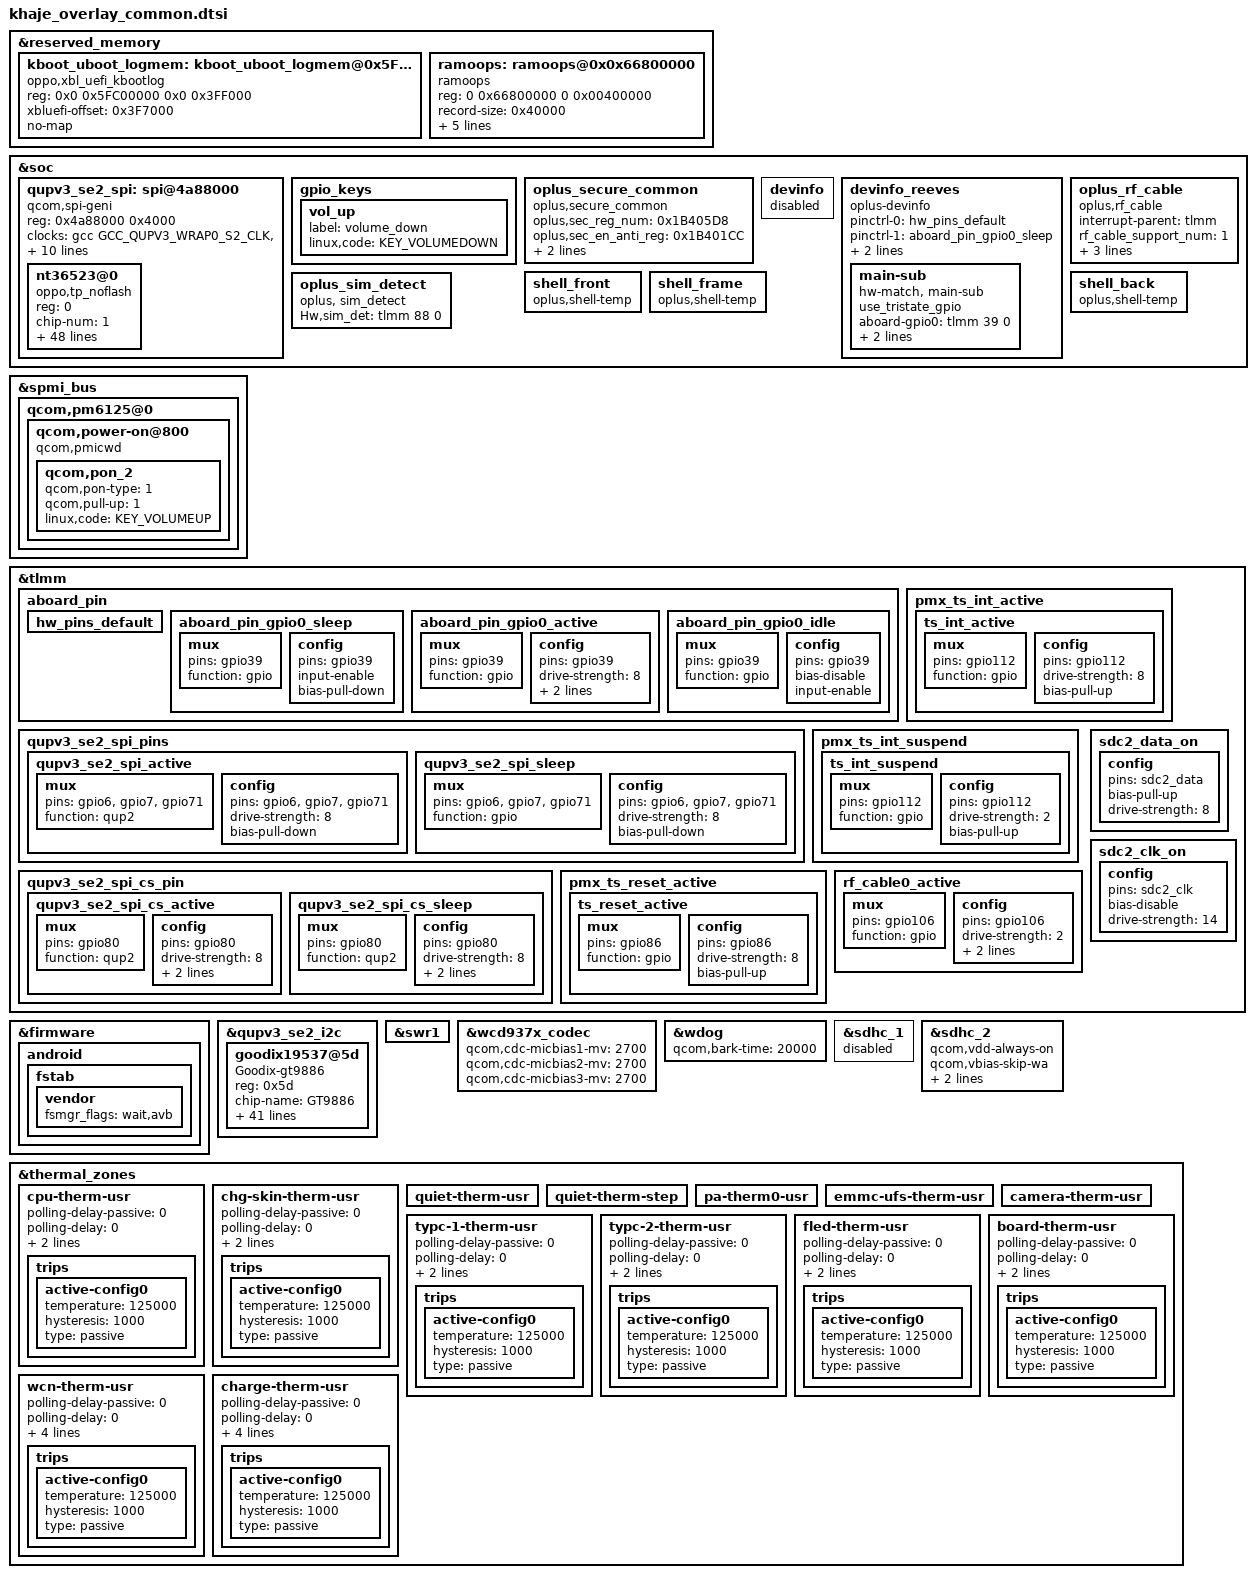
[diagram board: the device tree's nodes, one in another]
#include "dsi-panel-nt36523b-60hz-djn-reeves-fhd-video.dtsi"
#include "dsi-panel-nt36523w-60hz-inx-reeves-fhd-video.dtsi"
#include "camera/khaje-reeves-camera-overlay.dtsi"
#include "sensor/reeves-sensor-mtp.dtsi"

// xbl_uefi_mem address get from boot_images Core.dsc.inc file: PcdEmbeddedFdBaseAddress + SERIAL_BUFFER_OFFSET,0x5FC00000+0x3F7000
// kernel boot log: 0x5FC00000~ 0x5FFF7000
&reserved_memory {
	kboot_uboot_logmem: kboot_uboot_logmem@0x5FC00000 {
		reg = <0x0 0x5FC00000 0x0 0x3FF000>;
		compatible = "oppo,xbl_uefi_kbootlog";
		xbluefi-offset = <0x3F7000>;
		no-map;
	};

	ramoops: ramoops@0x0x66800000 {
		compatible = "ramoops";
		reg = <0 0x66800000 0 0x00400000>;
		record-size =  <0x40000>; //256x1024
		console-size = <0x40000>;
		ftrace-size =  <0x40000>;
		pmsg-size=         <0x200000>;
		devinfo-size=  <0x01000>;
		ecc-size=          <0x0>;
	};
};
//bengal-qrd.dtsi
&soc {
	qupv3_se2_spi: spi@4a88000 {
		compatible = "qcom,spi-geni";
		#address-cells = <1>;
		#size-cells = <0>;
		reg = <0x4a88000 0x4000>;
		reg-names = "se_phys";
		clock-names = "se-clk", "m-ahb", "s-ahb";
		clocks = <&gcc GCC_QUPV3_WRAP0_S2_CLK>,
		<&gcc GCC_QUPV3_WRAP_0_M_AHB_CLK>,
		<&gcc GCC_QUPV3_WRAP_0_S_AHB_CLK>;
		pinctrl-names = "default", "sleep";
		pinctrl-0 = <&qupv3_se2_spi_active &qupv3_se2_spi_cs_active>;
		pinctrl-1 = <&qupv3_se2_spi_sleep &qupv3_se2_spi_cs_sleep>;

		interrupts = <GIC_SPI 329 IRQ_TYPE_LEVEL_HIGH>;
		spi-max-frequency = <50000000>;
		qcom,wrapper-core = <&qupv3_0>;
		dmas = <&gpi_dma0 0 2 1 64 0>,
		<&gpi_dma0 1 2 1 64 0>;
		dma-names = "tx", "rx";
		status = "okay";
	};

	gpio_keys {
		vol_up {
			/delete-property/ label;
			label = "volume_down";
			/delete-property/ linux,code;
			linux,code = <KEY_VOLUMEDOWN>;
		};
	};

    // #ifdef OPLUS_FEATURE_SECURITY_COMMON
    oplus_secure_common {
	compatible = "oplus,secure_common";
	oplus,sec_reg_num = <0x1B405D8>;
	oplus,sec_en_anti_reg = <0x1B401CC>;
	oplus,sec_override1_reg = <0x7860C0>;
	oplus,override1_en_value = <0x1>;
    };
    //#endif /* OPLUS_FEATURE_SECURITY_COMMON */

        devinfo {
                status = "disabled";
        };
        devinfo_reeves {
                compatible = "oplus-devinfo";

                pinctrl-names = "default", "sleep", "active", "idle";
                pinctrl-0 = <&hw_pins_default>;
                pinctrl-1 = <&aboard_pin_gpio0_sleep>;
                pinctrl-2 = <&aboard_pin_gpio0_active>;
                pinctrl-3 = <&aboard_pin_gpio0_idle>;
                main-sub {
                        use_tristate_gpio;
                        compatible = "hw-match, main-sub";
                        aboard-gpio0 = <&tlmm 39 0>;
                        aboard-patterns = <2 2>;    /*0[high-resistance] 1[pull-down] 2[pull-up]*/
                        /*main board*/
                        match-projects = <21029 21030>;
                };
        };

	oplus_rf_cable {
		compatible = "oplus,rf_cable";
		interrupt-parent = <&tlmm>;
		rf_cable_support_num = <1>;
		rf,cable0-gpio = <&tlmm 106 0>;
		rf,cable-support-timer = <0>;
		pinctrl-names = "rf_cable_active";
		pinctrl-0 = <&rf_cable0_active>;
	};

    //#ifdef OPLUS_FEATURE_THERMAL_HORAE
    shell_front {
        compatible = "oplus,shell-temp";
    };

    shell_frame {
        compatible = "oplus,shell-temp";
    };

    shell_back {
        compatible = "oplus,shell-temp";
    };
    //#endif /* OPLUS_FEATURE_THERMAL_HORAE */

    //#ifdef OPLUS_FEATURE_TP_BASIC
	oplus_sim_detect {
		compatible = "oplus, sim_detect";
		Hw,sim_det = <&tlmm 88 0>;
	};
    //#endif /* OPLUS_FEATURE_TP_BASIC */

};
&spmi_bus {
	qcom,pm6125@0 {
		qcom,power-on@800 {
			qcom,pmicwd;
			qcom,pon_2 {
				qcom,pon-type = <1>;
				qcom,pull-up = <1>;
				linux,code = <KEY_VOLUMEUP>;
			};
		};
    };
};

&tlmm {
         aboard_pin {
                 hw_pins_default:hw_pins_default {
                 };
                 aboard_pin_gpio0_sleep:aboard_pin_gpio0_sleep {
                        mux {
                                pins = "gpio39";
                                function = "gpio";
                        };

                        config {
                                pins = "gpio39";
                                input-enable;
                                bias-pull-down;
                        };
                 };
                 aboard_pin_gpio0_active:aboard_pin_gpio0_active {
                        mux {
                                pins = "gpio39";
                                function = "gpio";
                        };

                        config {
                                pins = "gpio39";
                                drive-strength = <8>;
                                bias-pull-up;
				input-enable;
                        };
                 };
                 aboard_pin_gpio0_idle:aboard_pin_gpio0_idle {
                        mux {
                                pins = "gpio39";
                                function = "gpio";
                        };

                        config {
                                pins = "gpio39";
                                bias-disable;
				input-enable;
                        };
                 };
         };
	/delete-node/ qupv3_se2_i2c_pins;
	qupv3_se2_spi_pins: qupv3_se2_spi_pins {
		qupv3_se2_spi_active: qupv3_se2_spi_active {
			mux {
				pins = "gpio6", "gpio7", "gpio71";
				function = "qup2";
			};

			config {
				pins = "gpio6", "gpio7", "gpio71";
				drive-strength = <8>;
				bias-pull-down;
			};
		};

		qupv3_se2_spi_sleep: qupv3_se2_spi_sleep {
			mux {
				pins = "gpio6", "gpio7", "gpio71";
				function = "gpio";
			};

			config {
				pins = "gpio6", "gpio7", "gpio71";
				drive-strength = <8>;
				bias-pull-down;
			};
		};
	};

	qupv3_se2_spi_cs_pin: qupv3_se2_spi_cs_pin {
		qupv3_se2_spi_cs_active: qupv3_se2_spi_cs_active {
			mux {
				pins = "gpio80";
				function = "qup2";
			};

			config {
				pins = "gpio80";
				drive-strength = <8>;
				output-high;
				bias-pull-up;
			};
		};

		qupv3_se2_spi_cs_sleep: qupv3_se2_spi_cs_sleep {
			mux {
				pins = "gpio80";
				function = "qup2";
			};

			config {
				pins = "gpio80";
				drive-strength = <8>;
				output-high;
				bias-pull-up;
			};
		};
	};
	pmx_ts_int_active {
		ts_int_active: ts_int_active {
			mux {
				pins = "gpio112";
				function = "gpio";
			};

			config {
				pins = "gpio112";
				drive-strength = <8>;
				bias-pull-up;
			};
		};
	};

	pmx_ts_int_suspend {
		ts_int_suspend: ts_int_suspend {
			mux {
				pins = "gpio112";
				function = "gpio";
			};

			config {
				pins = "gpio112";
				drive-strength = <2>;
				bias-pull-up;
			};
		};
	};

	pmx_ts_reset_active {
		ts_reset_active: ts_reset_active {
			mux {
				pins = "gpio86";
				function = "gpio";
			};

			config {
				pins = "gpio86";
				drive-strength = <8>;
				bias-pull-up;
			};
		};
	};

	rf_cable0_active: rf_cable0_active {
		mux {
			pins = "gpio106";
			function = "gpio";
		};
		config {
			pins = "gpio106";
			drive-strength = <2>;
			input-enable;
			bias-pull-up;
		};
	};

	sdc2_data_on: sdc2_data_on {
		config {
			pins = "sdc2_data";
			bias-pull-up;           /* pull up */
			drive-strength = <8>;  /* 8 MA */
		};
	};
	sdc2_clk_on: sdc2_clk_on {
		config {
			pins = "sdc2_clk";
			bias-disable;           /* NO pull */
			drive-strength = <14>;  /* 14 MA */
		};
	};

};

&firmware {
	android {
		fstab {
			vendor {
				/delete-property/ fsmgr_flags;
				fsmgr_flags = "wait,avb";
			};
		};
	};
};

&qupv3_se2_i2c {
	#address-cells = <1>;
	#size-cells = <0>;

	status = "ok";
	goodix19537@5d {
		compatible = "Goodix-gt9886";
		reg = <0x5d>;
		chip-name = "GT9886";

		/* Interrupt && Irq-gpio */
		interrupt-parent = <&tlmm>;
		interrupts = <112 0x2002>;

		/* Power Config */
		enable2v8_gpio = <&tlmm 54 0x1>;
		vdd_2v8_volt = <3008000>;

		/* Interrupt && Irq-gpio */
		irq-gpio = <&tlmm 112 0x2002>;
		reset-gpio = <&tlmm 86 0x1>;
		pinctrl-names = "default";
		pinctrl-0 = <&ts_int_active &ts_reset_active>;
		//pinctrl-1 = <&ts_int_suspend>;

		touchpanel,max-num-support = <10>;
		touchpanel,tx-rx-num = <15 34>;
		touchpanel,panel-coords = <5400 12000>;
		touchpanel,display-coords = <1080 2400>;
		touchpanel,touchmajor-limit = <0 54>;
		touchpanel,smooth-level = <255 2 15 25 45 60>;
		touchpanel,sensitive-level = <255 20 14 10 6 0>;

		vid_len = <2>;
		project_id = <21029>;
		panel_type = <8>;
		tp_type = <8>;
		firmware_name = "0xAA31100";
		platform_support_project = <21029 21030>;
		platform_support_project_dir = <21029 21029 21029>;
		platform_support_project_commandline = "default_commandline","default_commandline","default_commandline";
                platform_support_project_external_name = "AA311", "AA311", "AA311";

		/* SW Support Feature Control */
		register-is-16bit;
		black_gesture_support;
		fw_edge_limit_support;
		pressure_report_support;
		charger_pump_support;
		game_switch_support;
		smart_gesture_support;
		fw_update_app_support;
		fingerprint_underscreen_support;
		esd_handle_support;
		goodix_detail_debug_info_support;
		health_monitor_v2_support;
		/*
		 *Virtual Key Config:
		 *1:touchpanel,button-type: <virtualkey_type  supportted_button-map>
		 *virtualkey_type:
		 *Type 1: using board_properties
		 *Type 2: using same IC (button zone&& touch zone are seprate)
		 *Type 3: using diffrent IC (button zone&& touch zone are seprate)
		 *Type 4: No need of virtual key process
		 *supportted_button-map:select|menu|home|back
		 *
		 *2:touchpanel,button-map
		 *type (X1,Y1)(X2,Y2)(X3,Y3)(Width_X,Hight_Y)--Only when button-type is 0
		 */
		touchpanel,button-type = <4>;
		touchpanel.button-TRx = <0 0>;
	};
};

&qupv3_se2_spi {
	status = "okay";
	nt36523@0 {
		status = "okay";
		compatible = "oppo,tp_noflash";
		reg = <0>;
		chip-num = <1>;
		chip-name = "NT36523";
		project_id = <21029>;
		spi-max-frequency = <12000000>; //4800000,9600000,15000000,19200000
		interrupt-parent = <&tlmm>;
		interrupts = <112 0x0>;
		irq-gpio = <&tlmm 112 0x2002>;
		reset-gpio = <&tlmm 86 0x00>;

		//lcd-reset-gpio = <&tlmm 85 0x00>;
		//cs-gpio = <&tlmm 80 0x00>;

		touchpanel,max-num-support = <10>;
		touchpanel,tx-rx-num = <30 48>;
		touchpanel,panel-coords = <1200 2000>;
		touchpanel,display-coords = <1200 2000>;
		touchpanel,touchmajor-limit = <0 54>;

		touchpanel,pen-tx-rx-num = <4 6>;
		touchpanel,pen-panel-coords = <2400 4000>;
		touchpanel,pen-max-pressure = <4096>;
		touchpanel,pen-max-tilt = <60 60>;
		touchpanel,msecs-to-jiffies-time = <100>;
		tp_type = <20>;//INX

		platform_support_project = <21029 21030>;
		platform_support_project_dir = <21029 21029>;
		platform_support_commandline = "default_commandline","default_commandline";
		platform_support_project_commandline = "default_commandline","default_commandline";
		platform_support_project_external_name = "FA261","FA261";
		vid_len = <7>;

		pinctrl-names = "default", "suspend";
		pinctrl-0 = <&ts_int_active &ts_reset_active>;
		pinctrl-1 = <&ts_int_suspend &ts_reset_suspend>;

		incell_screen;
		//iovcc_shutdown_support;
		fw_edge_limit_support;
		black_gesture_support;
		charger_pump_support;
		headset_pump_support;
		esd_handle_support;
		black_gesture_test_support;
		game_switch_support;
		noflash_support;
		lcd_trigger_load_tp_fw_support;
		smart_gesture_support;
		pressure_report_support;
		pen_support;
		irq_need_dev_resume_ok;
		fw_update_app_support;
		health_monitor_v2_support;
		fw_update_in_probe_with_headfile;
		black_gesture_indep_support;
		touchpanel,button-type = <4>;
	};
};

&swr1 {
	/delete-property/ qcom,disable-div2-clk-switch;
};
&wcd937x_codec {
	/delete-property/ qcom,cdc-micbias1-mv;
	/delete-property/ qcom,cdc-micbias2-mv;
	/delete-property/ qcom,cdc-micbias3-mv;
	qcom,cdc-micbias1-mv = <2700>;
	qcom,cdc-micbias2-mv = <2700>;
	qcom,cdc-micbias3-mv = <2700>;
};

//modify bark time to 20s
&wdog {
	/delete-property/ qcom,bark-time;
	qcom,bark-time = <20000>;
};

/* #ifdef OPLUS_FEATURE_EMMC_DRIVER */
&sdhc_1 {
       status = "disabled";
};

&sdhc_2 {
        qcom,vdd-always-on;
        qcom,vbias-skip-wa;
        cd-gpios = <&tlmm 88 GPIO_ACTIVE_HIGH>;
        pwr-gpios = <&tlmm 17 0>;
        status = "ok";
};
/* #endif */
//#ifdef OPLUS_TEMP_NTC
&thermal_zones {
        cpu-therm-usr {
                polling-delay-passive = <0>;
                polling-delay = <0>;
                thermal-governor = "user_space";
                wake-capable-sensor;
                trips {
                        active-config0 {
                                temperature = <125000>;
                                hysteresis = <1000>;
                                type = "passive";
                        };
                };
        };

        chg-skin-therm-usr {
                polling-delay-passive = <0>;
                polling-delay = <0>;
                thermal-governor = "user_space";
                wake-capable-sensor;
                trips {
                        active-config0 {
                                temperature = <125000>;
                                hysteresis = <1000>;
                                type = "passive";
                        };
                };
        };

        quiet-therm-usr {
                /delete-property/ thermal-sensors;
        };

		quiet-therm-step {
                /delete-property/ thermal-sensors;
        };

		pa-therm0-usr {
                /delete-property/ thermal-sensors;
        };

		emmc-ufs-therm-usr {
                /delete-property/ thermal-sensors;
        };

        camera-therm-usr {
                /delete-property/ thermal-sensors;
        };

        typc-1-therm-usr {
                polling-delay-passive = <0>;
                polling-delay = <0>;
                thermal-governor = "user_space";
                wake-capable-sensor;
                trips {
                        active-config0 {
                                temperature = <125000>;
                                hysteresis = <1000>;
                                type = "passive";
                        };
                };
        };

        typc-2-therm-usr {
                polling-delay-passive = <0>;
                polling-delay = <0>;
                thermal-governor = "user_space";
                wake-capable-sensor;
                trips {
                        active-config0 {
                                temperature = <125000>;
                                hysteresis = <1000>;
                                type = "passive";
                        };
                };
        };

        fled-therm-usr {
                polling-delay-passive = <0>;
                polling-delay = <0>;
                thermal-governor = "user_space";
                wake-capable-sensor;
                trips {
                        active-config0 {
                                temperature = <125000>;
                                hysteresis = <1000>;
                                type = "passive";
                        };
                };
        };

        board-therm-usr {
                polling-delay-passive = <0>;
                polling-delay = <0>;
                thermal-governor = "user_space";
                wake-capable-sensor;
                trips {
                        active-config0 {
                                temperature = <125000>;
                                hysteresis = <1000>;
                                type = "passive";
                        };
                };
        };

        wcn-therm-usr {
                polling-delay-passive = <0>;
                polling-delay = <0>;
                thermal-governor = "user_space";
                thermal-sensors = <&pm6125_adc_tm ADC_AMUX_THM1_PU2>;
                wake-capable-sensor;
                trips {
                        active-config0 {
                                temperature = <125000>;
                                hysteresis = <1000>;
                                type = "passive";
                        };
                };
        };

        charge-therm-usr {
                polling-delay-passive = <0>;
                polling-delay = <0>;
                thermal-governor = "user_space";
                thermal-sensors = <&pm6125_adc_tm ADC_AMUX_THM2_PU2>;
                wake-capable-sensor;
                trips {
                        active-config0 {
                                temperature = <125000>;
                                hysteresis = <1000>;
                                type = "passive";
                        };
                };
        };

};
//#endif
